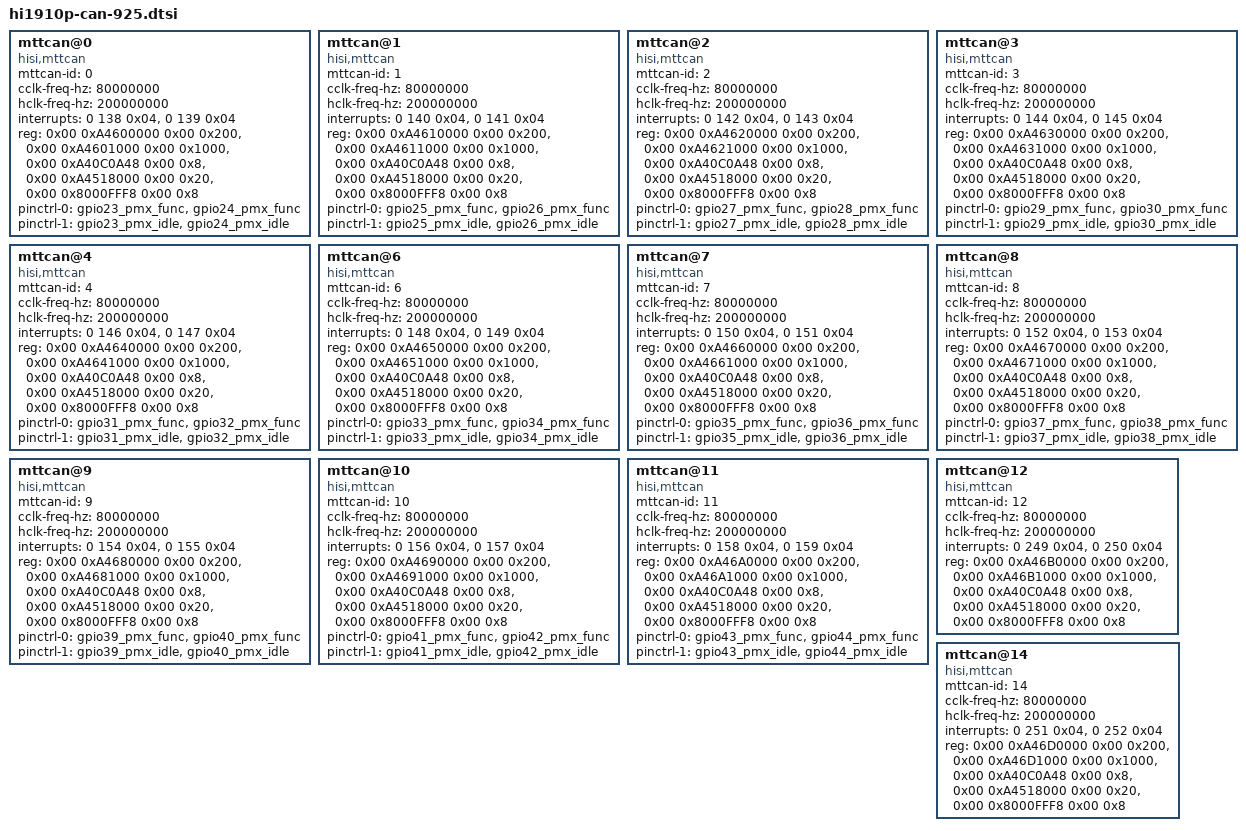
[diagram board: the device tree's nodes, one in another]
    mttcan@0 {
        compatible = "hisi,mttcan";
        mttcan-id = <0>;
        cclk-freq-hz = <80000000>;
        hclk-freq-hz = <200000000>;
        interrupts = <0 138 0x04>,
                     <0 139 0x04>;
        interrupt-names = "int0", "int1";
        reg = <0x00 0xA4600000 0x00 0x200>,
              <0x00 0xA4601000 0x00 0x1000>,
              <0x00 0xA40C0A48 0x00 0x8>,
              <0x00 0xA4518000 0x00 0x20>,
              <0x00 0x8000FFF8 0x00 0x8>;
        reg-names = "reg-base", "mram-base", "reset-base", "gpio-base", "plat-base";
        pinctrl-names = "default", "idle";
        pinctrl-0 = <&gpio23_pmx_func &gpio24_pmx_func>;
        pinctrl-1 = <&gpio23_pmx_idle &gpio24_pmx_idle>;
    };

    mttcan@1 {
        compatible = "hisi,mttcan";
        mttcan-id = <1>;
        cclk-freq-hz = <80000000>;
        hclk-freq-hz = <200000000>;
        interrupts = <0 140 0x04>,
                     <0 141 0x04>;
        interrupt-names = "int0", "int1";
        reg = <0x00 0xA4610000 0x00 0x200>,
              <0x00 0xA4611000 0x00 0x1000>,
              <0x00 0xA40C0A48 0x00 0x8>,
              <0x00 0xA4518000 0x00 0x20>,
              <0x00 0x8000FFF8 0x00 0x8>;
        reg-names = "reg-base", "mram-base", "reset-base", "gpio-base", "plat-base";
        pinctrl-names = "default", "idle";
        pinctrl-0 = <&gpio25_pmx_func &gpio26_pmx_func>;
        pinctrl-1 = <&gpio25_pmx_idle &gpio26_pmx_idle>;
    };

    mttcan@2 {
        compatible = "hisi,mttcan";
        mttcan-id = <2>;
        cclk-freq-hz = <80000000>;
        hclk-freq-hz = <200000000>;
        interrupts = <0 142 0x04>,
                     <0 143 0x04>;
        interrupt-names = "int0", "int1";
        reg = <0x00 0xA4620000 0x00 0x200>,
              <0x00 0xA4621000 0x00 0x1000>,
              <0x00 0xA40C0A48 0x00 0x8>,
              <0x00 0xA4518000 0x00 0x20>,
              <0x00 0x8000FFF8 0x00 0x8>;
        reg-names = "reg-base", "mram-base", "reset-base", "gpio-base", "plat-base";
        pinctrl-names = "default", "idle";
        pinctrl-0 = <&gpio27_pmx_func &gpio28_pmx_func>;
        pinctrl-1 = <&gpio27_pmx_idle &gpio28_pmx_idle>;
    };

    mttcan@3 {
        compatible = "hisi,mttcan";
        mttcan-id = <3>;
        cclk-freq-hz = <80000000>;
        hclk-freq-hz = <200000000>;
        interrupts = <0 144 0x04>,
                     <0 145 0x04>;
        interrupt-names = "int0", "int1";
        reg = <0x00 0xA4630000 0x00 0x200>,
              <0x00 0xA4631000 0x00 0x1000>,
              <0x00 0xA40C0A48 0x00 0x8>,
              <0x00 0xA4518000 0x00 0x20>,
              <0x00 0x8000FFF8 0x00 0x8>;
        reg-names = "reg-base", "mram-base", "reset-base", "gpio-base", "plat-base";
        pinctrl-names = "default", "idle";
        pinctrl-0 = <&gpio29_pmx_func &gpio30_pmx_func>;
        pinctrl-1 = <&gpio29_pmx_idle &gpio30_pmx_idle>;
    };

    mttcan@4 {
        compatible = "hisi,mttcan";
        mttcan-id = <4>;
        cclk-freq-hz = <80000000>;
        hclk-freq-hz = <200000000>;
        interrupts = <0 146 0x04>,
                     <0 147 0x04>;
        interrupt-names = "int0", "int1";
        reg = <0x00 0xA4640000 0x00 0x200>,
              <0x00 0xA4641000 0x00 0x1000>,
              <0x00 0xA40C0A48 0x00 0x8>,
              <0x00 0xA4518000 0x00 0x20>,
              <0x00 0x8000FFF8 0x00 0x8>;
        reg-names = "reg-base", "mram-base", "reset-base", "gpio-base", "plat-base";
        pinctrl-names = "default", "idle";
        pinctrl-0 = <&gpio31_pmx_func &gpio32_pmx_func>;
        pinctrl-1 = <&gpio31_pmx_idle &gpio32_pmx_idle>;
    };

    mttcan@6 {
        compatible = "hisi,mttcan";
        mttcan-id = <6>;
        cclk-freq-hz = <80000000>;
        hclk-freq-hz = <200000000>;
        interrupts = <0 148 0x04>,
                     <0 149 0x04>;
        interrupt-names = "int0", "int1";
        reg = <0x00 0xA4650000 0x00 0x200>,
              <0x00 0xA4651000 0x00 0x1000>,
              <0x00 0xA40C0A48 0x00 0x8>,
              <0x00 0xA4518000 0x00 0x20>,
              <0x00 0x8000FFF8 0x00 0x8>;
        reg-names = "reg-base", "mram-base", "reset-base", "gpio-base", "plat-base";
        pinctrl-names = "default", "idle";
        pinctrl-0 = <&gpio33_pmx_func &gpio34_pmx_func>;
        pinctrl-1 = <&gpio33_pmx_idle &gpio34_pmx_idle>;
    };

    mttcan@7 {
        compatible = "hisi,mttcan";
        mttcan-id = <7>;
        cclk-freq-hz = <80000000>;
        hclk-freq-hz = <200000000>;
        interrupts = <0 150 0x04>,
                     <0 151 0x04>;
        interrupt-names = "int0", "int1";
        reg = <0x00 0xA4660000 0x00 0x200>,
              <0x00 0xA4661000 0x00 0x1000>,
              <0x00 0xA40C0A48 0x00 0x8>,
              <0x00 0xA4518000 0x00 0x20>,
              <0x00 0x8000FFF8 0x00 0x8>;
        reg-names = "reg-base", "mram-base", "reset-base", "gpio-base", "plat-base";
        pinctrl-names = "default", "idle";
        pinctrl-0 = <&gpio35_pmx_func &gpio36_pmx_func>;
        pinctrl-1 = <&gpio35_pmx_idle &gpio36_pmx_idle>;
    };

    mttcan@8 {
        compatible = "hisi,mttcan";
        mttcan-id = <8>;
        cclk-freq-hz = <80000000>;
        hclk-freq-hz = <200000000>;
        interrupts = <0 152 0x04>,
                     <0 153 0x04>;
        interrupt-names = "int0", "int1";
        reg = <0x00 0xA4670000 0x00 0x200>,
              <0x00 0xA4671000 0x00 0x1000>,
              <0x00 0xA40C0A48 0x00 0x8>,
              <0x00 0xA4518000 0x00 0x20>,
              <0x00 0x8000FFF8 0x00 0x8>;
        reg-names = "reg-base", "mram-base", "reset-base", "gpio-base", "plat-base";
        pinctrl-names = "default", "idle";
        pinctrl-0 = <&gpio37_pmx_func &gpio38_pmx_func>;
        pinctrl-1 = <&gpio37_pmx_idle &gpio38_pmx_idle>;
    };

    mttcan@9 {
        compatible = "hisi,mttcan";
        mttcan-id = <9>;
        cclk-freq-hz = <80000000>;
        hclk-freq-hz = <200000000>;
        interrupts = <0 154 0x04>,
                     <0 155 0x04>;
        interrupt-names = "int0", "int1";
        reg = <0x00 0xA4680000 0x00 0x200>,
              <0x00 0xA4681000 0x00 0x1000>,
              <0x00 0xA40C0A48 0x00 0x8>,
              <0x00 0xA4518000 0x00 0x20>,
              <0x00 0x8000FFF8 0x00 0x8>;
        reg-names = "reg-base", "mram-base", "reset-base", "gpio-base", "plat-base";
        pinctrl-names = "default", "idle";
        pinctrl-0 = <&gpio39_pmx_func &gpio40_pmx_func>;
        pinctrl-1 = <&gpio39_pmx_idle &gpio40_pmx_idle>;
    };

    mttcan@10 {
        compatible = "hisi,mttcan";
        mttcan-id = <10>;
        cclk-freq-hz = <80000000>;
        hclk-freq-hz = <200000000>;
        interrupts = <0 156 0x04>,
                     <0 157 0x04>;
        interrupt-names = "int0", "int1";
        reg = <0x00 0xA4690000 0x00 0x200>,
              <0x00 0xA4691000 0x00 0x1000>,
              <0x00 0xA40C0A48 0x00 0x8>,
              <0x00 0xA4518000 0x00 0x20>,
              <0x00 0x8000FFF8 0x00 0x8>;
        reg-names = "reg-base", "mram-base", "reset-base", "gpio-base", "plat-base";
        pinctrl-names = "default", "idle";
        pinctrl-0 = <&gpio41_pmx_func &gpio42_pmx_func>;
        pinctrl-1 = <&gpio41_pmx_idle &gpio42_pmx_idle>;
    };

    mttcan@11 {
        compatible = "hisi,mttcan";
        mttcan-id = <11>;
        cclk-freq-hz = <80000000>;
        hclk-freq-hz = <200000000>;
        interrupts = <0 158 0x04>,
                     <0 159 0x04>;
        interrupt-names = "int0", "int1";
        reg = <0x00 0xA46A0000 0x00 0x200>,
              <0x00 0xA46A1000 0x00 0x1000>,
              <0x00 0xA40C0A48 0x00 0x8>,
              <0x00 0xA4518000 0x00 0x20>,
              <0x00 0x8000FFF8 0x00 0x8>;
        reg-names = "reg-base", "mram-base", "reset-base", "gpio-base", "plat-base";
        pinctrl-names = "default", "idle";
        pinctrl-0 = <&gpio43_pmx_func &gpio44_pmx_func>;
        pinctrl-1 = <&gpio43_pmx_idle &gpio44_pmx_idle>;
    };

    mttcan@12 {
        compatible = "hisi,mttcan";
        mttcan-id = <12>;
        cclk-freq-hz = <80000000>;
        hclk-freq-hz = <200000000>;
        interrupts = <0 249 0x04>,
                     <0 250 0x04>;
        interrupt-names = "int0", "int1";
        reg = <0x00 0xA46B0000 0x00 0x200>,
              <0x00 0xA46B1000 0x00 0x1000>,
              <0x00 0xA40C0A48 0x00 0x8>,
              <0x00 0xA4518000 0x00 0x20>,
              <0x00 0x8000FFF8 0x00 0x8>;
        reg-names = "reg-base", "mram-base", "reset-base", "gpio-base", "plat-base";
    };

    mttcan@14 {
        compatible = "hisi,mttcan";
        mttcan-id = <14>;
        cclk-freq-hz = <80000000>;
        hclk-freq-hz = <200000000>;
        interrupts = <0 251 0x04>,
                     <0 252 0x04>;
        interrupt-names = "int0", "int1";
        reg = <0x00 0xA46D0000 0x00 0x200>,
              <0x00 0xA46D1000 0x00 0x1000>,
              <0x00 0xA40C0A48 0x00 0x8>,
              <0x00 0xA4518000 0x00 0x20>,
              <0x00 0x8000FFF8 0x00 0x8>;
        reg-names = "reg-base", "mram-base", "reset-base", "gpio-base", "plat-base";
    };
